AUTOSAR XML (schema 4-1-3)
standard types defined: boolean, sint8, uint16, uint32, uint8, boolean_CompuMethod, boolean_DataConstr, sint8_DataConstr, uint16_DataConstr, uint32_DataConstr, uint8_DataConstr, sint16
package /MICROSAR/Dem_swc/DataTypes
  5 x impl type:
    Dem_DebounceResetStatusType: compu {0=DEM_DEBOUNCE_STATUS_FREEZE, 1=DEM_DEBOUNCE_STATUS_RESET}, range raw 0..255, implementation-data-type=ImplementationDataTypes/uint8
    Dem_DTCFormatType: compu {0=DEM_DTC_FORMAT_OBD, 1=DEM_DTC_FORMAT_UDS, 2=DEM_DTC_FORMAT_J1939}, range raw 0..2, implementation-data-type=ImplementationDataTypes/uint8
    Dem_EventStatusType:
      compu {0=DEM_EVENT_STATUS_PASSED, 1=DEM_EVENT_STATUS_FAILED, 2=DEM_EVENT_STATUS_PREPASSED, 3=DEM_EVENT_STATUS_PREFAILED, 4=DEM_EVENT_STATUS_FDC_THRESHOLD_REACHED, 5=DEM_EVENT_STATUS_PASSED_CONDITIONS_NOT_FULFILLED, 6=DEM_EVENT_STATUS_FAILED_CONDITIONS_NOT_FULFILLED, 7=DEM_EVENT_STATUS_PREPASSED_CONDITIONS_NOT_FULFILLED, 8=DEM_EVENT_STATUS_PREFAILED_CONDITIONS_NOT_FULFILLED}
      range raw 0..255
      implementation-data-type=ImplementationDataTypes/uint8
    Dem_MaxDataValueType: category=ARRAY, sw-calibration-access=READ-ONLY
      element Dem_MaxDataValueTypeElement: array-size=40, array-size-semantics=FIXED-SIZE, implementation-data-type=ImplementationDataTypes/uint8
    Dem_UdsStatusByteType:
      compu {mask 1: 1=DEM_UDS_STATUS_TF (bit 0: TestFailed), mask 2: 2=DEM_UDS_STATUS_TFTOC (bit 1: TestFailedThisOperationCycle), mask 4: 4=DEM_UDS_STATUS_PDTC (bit 2: PendingDTC), mask 8: 8=DEM_UDS_STATUS_CDTC (bit 3: ConfirmedDTC), mask 16: 16=DEM_UDS_STATUS_TNCSLC (bit 4: TestNotCompletedSinceLastClear), mask 32: 32=DEM_UDS_STATUS_TFSLC (bit 5: TestFailedSinceLastClear), mask 64: 64=DEM_UDS_STATUS_TNCTOC (bit 6: TestNotCompletedThisOperationCycle), mask 128: 128=DEM_UDS_STATUS_WIR (bit 7: WarningIndicatorRequested)}
      range raw 0..255
      implementation-data-type=ImplementationDataTypes/uint8
package /MICROSAR/Dem_swc/Interfaces
  client server interface DiagnosticMonitor: is-service=true, service-kind=DIAGNOSTIC-EVENT-MANAGER
    11 x operation:
      GetDTCOfEvent: possible-error=[DEM_E_NO_DTC_AVAILABLE, DiagnosticMonitor/E_NOT_OK]
        arg DTCFormat: type=Dem_DTCFormatType, direction=IN, server-argument-impl-policy=USE-ARGUMENT-TYPE
        arg DTCOfEvent: type=uint32, direction=OUT, server-argument-impl-policy=USE-ARGUMENT-TYPE
      GetEventExtendedDataRecordEx: possible-error=[DEM_BUFFER_TOO_SMALL, DEM_NO_SUCH_ELEMENT, DiagnosticMonitor/E_NOT_OK]
        arg RecordNumber: type=ImplementationDataTypes/uint8, direction=IN, server-argument-impl-policy=USE-ARGUMENT-TYPE
        arg DestBuffer: type=Dem_MaxDataValueType, direction=OUT, server-argument-impl-policy=USE-ARGUMENT-TYPE
        arg BufSize: type=ImplementationDataTypes/uint16, direction=INOUT, server-argument-impl-policy=USE-ARGUMENT-TYPE
      GetEventFailed: possible-error=DiagnosticMonitor/E_NOT_OK
        arg EventFailed: type=ImplementationDataTypes/boolean, direction=OUT, server-argument-impl-policy=USE-ARGUMENT-TYPE
      GetEventFreezeFrameDataEx: possible-error=[DEM_BUFFER_TOO_SMALL, DEM_NO_SUCH_ELEMENT, DiagnosticMonitor/E_NOT_OK]
        4 x arg, all with server-argument-impl-policy=USE-ARGUMENT-TYPE:
          RecordNumber: type=ImplementationDataTypes/uint8, direction=IN
          DataId: type=ImplementationDataTypes/uint16, direction=IN
          DestBuffer: type=Dem_MaxDataValueType, direction=OUT
          BufSize: type=ImplementationDataTypes/uint16, direction=INOUT
      GetEventStatus: possible-error=DiagnosticMonitor/E_NOT_OK
        arg UDSStatusByte: type=Dem_UdsStatusByteType, direction=OUT, server-argument-impl-policy=USE-ARGUMENT-TYPE
      GetEventTested: possible-error=DiagnosticMonitor/E_NOT_OK
        arg EventTested: type=ImplementationDataTypes/boolean, direction=OUT, server-argument-impl-policy=USE-ARGUMENT-TYPE
      GetEventUdsStatus: possible-error=DiagnosticMonitor/E_NOT_OK
        arg UDSStatusByte: type=Dem_UdsStatusByteType, direction=OUT, server-argument-impl-policy=USE-ARGUMENT-TYPE
      GetFaultDetectionCounter: possible-error=[DEM_E_NO_FDC_AVAILABLE, DiagnosticMonitor/E_NOT_OK]
        arg FaultDetectionCounter: type=sint8, direction=OUT, server-argument-impl-policy=USE-ARGUMENT-TYPE
      ResetEventDebounceStatus: possible-error=DiagnosticMonitor/E_NOT_OK
        arg DebounceResetStatus: type=Dem_DebounceResetStatusType, direction=IN, server-argument-impl-policy=USE-ARGUMENT-TYPE
      ResetEventStatus: possible-error=DiagnosticMonitor/E_NOT_OK
      SetEventStatus: possible-error=DiagnosticMonitor/E_NOT_OK
        arg EventStatus: type=Dem_EventStatusType, direction=IN, server-argument-impl-policy=USE-ARGUMENT-TYPE
    5 x error:
      DEM_BUFFER_TOO_SMALL: error-code=21
      DEM_E_NO_DTC_AVAILABLE: error-code=10
      DEM_E_NO_FDC_AVAILABLE: error-code=14
      DEM_NO_SUCH_ELEMENT: error-code=48
      E_NOT_OK: error-code=1
package /UAES/ASW/ApplicationDataTypes
  app type Appl_AcChrgrIntkT2_tTrfSnsr_CUR: category=CURVE, sw-calibration-access=READ-WRITE, sw-calprm-axis-set={sw-axis-index=1, category=COM_AXIS, sw-axis-individual={compu {phys=raw for raw -INF..INF; unit mV}, sw-max-axis-points=30, sw-min-axis-points=30, range raw 0..65535}}, compu {phys=raw*0.1-273.14 for raw -INF..INF; unit DegC}, range raw -32768..32767
  app type T_q0p1_o273p14_DegC_s16: category=VALUE, sw-calibration-access=READ-WRITE, compu {phys=raw*0.1-273.14 for raw -INF..INF; unit DegC}, range raw -32768..32767
  app type U_q1_mV_u16: category=VALUE, sw-calibration-access=READ-WRITE, compu {phys=raw for raw -INF..INF; unit mV}, range raw 0..65535
package /UAES/ASW/CompuMethods
  compu method CM_boolean: 0=FALSE, 1=TRUE
package /UAES/ASW/DataConstrs
  range DC_boolean: raw 0..1
  range DC_sint16: raw -32768..32767
  range DC_uint16: phys 0..6553.5, raw 0..65535
  range DC_uint8: raw 0..255
package /UAES/ASW/DataTypeMappingSets
  data type mapping set DTMS_AcChrgrIntkT2_DD
    data-type-maps:
      application-data-type=Appl_AcChrgrIntkT2_tTrfSnsr_CUR, implementation-data-type=AcChrgrIntkT2_tTrfSnsr_CUR_Type
      application-data-type=T_q0p1_o273p14_DegC_s16, implementation-data-type=sint16
      application-data-type=U_q1_mV_u16, implementation-data-type=ImplementationDataTypes/uint16
package /UAES/ASW/ImplementationDataTypes
  5 x impl type:
    AcChrgrIntkT2_tTrfSnsr_CUR_Type: category=STRUCTURE
      element N1: implementation-data-type=ImplementationDataTypes/uint16
      element BP1: implementation-data-type=rt_Array_U_q1_mV_u16_30
      element Table: implementation-data-type=rt_Array_T_q0p1_o273p14_DegC_s16_30
    rt_Array_T_q0p1_o273p14_DegC_s16_30: category=ARRAY
      element rt_Array_T_q0p1_o273p14_DegC_s16_30: array-size=30, array-size-semantics=FIXED-SIZE, implementation-data-type=T_q0p1_o273p14_DegC_s16
    rt_Array_U_q1_mV_u16_30: category=ARRAY
      element rt_Array_U_q1_mV_u16_30: array-size=30, array-size-semantics=FIXED-SIZE, implementation-data-type=U_q1_mV_u16
    T_q0p1_o273p14_DegC_s16: category=VALUE, base-type=sint16, range raw -32768..32767
    U_q1_mV_u16: category=VALUE, base-type=BaseTypes/uint16, range raw 0..65535
package /UAES/ASW/ImplementationDataTypes/Ground
  4 x constant specification:
    AcChrgrIntkT2_numRawVoltFildPoint_C: value-spec=AcChrgrIntkT2_numRawVoltFildPoint_C:10
    AcChrgrIntkT2_tTrfSnsr_CUR: value-spec=fields=[N:30, X:[10, 13, 16, 20, 25, 33, 42, 55, 73, 99, 136, 170, 213, 272, 345, 438, 560, 715, 911, 1160, 1469, 1840, 2269, 2739, 3221, 3676, 4069, 4380, 4611, 4769], Y:[5731, 5581, 5431, 5281, 5131, 4981, 4831, 4681, 4531, 4381, 4231, 4131, 4031, 3931, 3831, 3731, 3631, 3531, 3431, 3331, 3231, 3131, 3031, 2931, 2831, 2731, 2631, 2531, 2431, 2331]]
    AcChrgrIntkT2_uRawMaxSRC_C: value-spec=4800 mV
    AcChrgrIntkT2_uRawMinSRC_C: value-spec=200 mV
package /UAES/ASW/PortInterfaces
  client server interface IoHwAb_IoSigAdc
    operation Adc_Get: possible-error=IoHwAb_IoSigAdc/E_NOT_OK
      arg id_u16: type=ImplementationDataTypes/uint16, direction=IN, server-argument-impl-policy=USE-ARGUMENT-TYPE
      arg val_s16: type=sint16, direction=OUT, server-argument-impl-policy=USE-ARGUMENT-TYPE
    operation AdcFac_Get: possible-error=IoHwAb_IoSigAdc/E_NOT_OK
      arg id_u16: type=ImplementationDataTypes/uint16, direction=IN, server-argument-impl-policy=USE-ARGUMENT-TYPE
      arg val_s16: type=sint16, direction=OUT, server-argument-impl-policy=USE-ARGUMENT-TYPE
    operation AdcVRMBatt_Get: possible-error=IoHwAb_IoSigAdc/E_NOT_OK
      arg id_u16: type=ImplementationDataTypes/uint16, direction=IN, server-argument-impl-policy=USE-ARGUMENT-TYPE
      arg val_u8: type=ImplementationDataTypes/uint8, direction=OUT, server-argument-impl-policy=USE-ARGUMENT-TYPE
    error E_NOT_OK: error-code=1
  6 x sender receiver interface:
    AcChrgrIntkT2_flgSRCMaxErr: invalidation-policy{data-element=AcChrgrIntkT2_flgSRCMaxErr/Val, handle-invalid=DONT-INVALIDATE}
      data Val: sw-calibration-access=READ-ONLY, type=ImplementationDataTypes/boolean
    AcChrgrIntkT2_flgSRCMinErr: invalidation-policy{data-element=AcChrgrIntkT2_flgSRCMinErr/Val, handle-invalid=DONT-INVALIDATE}
      data Val: sw-calibration-access=READ-ONLY, type=ImplementationDataTypes/boolean
    AcChrgrIntkT2_t: invalidation-policy{data-element=AcChrgrIntkT2_t/Val, handle-invalid=DONT-INVALIDATE}
      data Val: sw-calibration-access=READ-ONLY, type=T_q0p1_o273p14_DegC_s16
    AcChrgrIntkT2_uRaw: invalidation-policy{data-element=AcChrgrIntkT2_uRaw/Val, handle-invalid=DONT-INVALIDATE}
      data Val: sw-calibration-access=READ-ONLY, type=U_q1_mV_u16
    BattU_bVoltEnbPinDiag: invalidation-policy{data-element=BattU_bVoltEnbPinDiag/Val, handle-invalid=DONT-INVALIDATE}
      data Val: sw-calibration-access=READ-ONLY, type=ImplementationDataTypes/boolean
    VehCoorn_stPwrMod: invalidation-policy{data-element=VehCoorn_stPwrMod/Val, handle-invalid=DONT-INVALIDATE}
      data Val: sw-calibration-access=READ-ONLY, type=ImplementationDataTypes/uint8
package /UAES/ASW/SwAddrMethods
  sw addr method CALDATA
package /UAES/ASW/SwComponentTypes
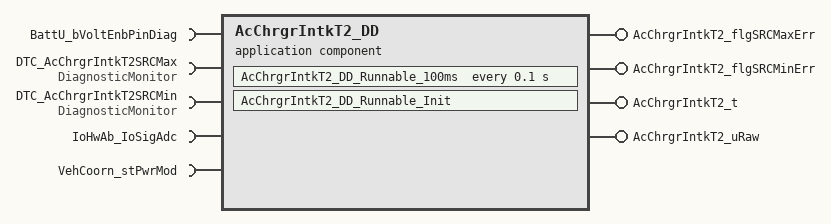
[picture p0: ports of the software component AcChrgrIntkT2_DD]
  application sw component type AcChrgrIntkT2_DD
    4 x provide port:
      AcChrgrIntkT2_flgSRCMaxErr: nonqueued-sender-com-spec{data-element=AcChrgrIntkT2_flgSRCMaxErr/Val, init-value=0}, provided-interface=AcChrgrIntkT2_flgSRCMaxErr
      AcChrgrIntkT2_flgSRCMinErr: nonqueued-sender-com-spec{data-element=AcChrgrIntkT2_flgSRCMinErr/Val, init-value=0}, provided-interface=AcChrgrIntkT2_flgSRCMinErr
      AcChrgrIntkT2_t: nonqueued-sender-com-spec{data-element=AcChrgrIntkT2_t/Val, init-value=0 DegC}, provided-interface=AcChrgrIntkT2_t
      AcChrgrIntkT2_uRaw: nonqueued-sender-com-spec{data-element=AcChrgrIntkT2_uRaw/Val, init-value=0 mV}, provided-interface=AcChrgrIntkT2_uRaw
    5 x require port:
      BattU_bVoltEnbPinDiag: nonqueued-receiver-com-spec{data-element=BattU_bVoltEnbPinDiag/Val, filter=data-filter-type=ALWAYS, init-value=0}, required-interface=BattU_bVoltEnbPinDiag
      DTC_AcChrgrIntkT2SRCMax: required-interface=DiagnosticMonitor
        required-com-specs:
          GetDTCOfEvent
          GetEventExtendedDataRecordEx
          GetEventFailed
          GetEventFreezeFrameDataEx
          GetEventStatus
          GetEventTested
          GetEventUdsStatus
          GetFaultDetectionCounter
          ResetEventDebounceStatus
          ResetEventStatus
          SetEventStatus
      DTC_AcChrgrIntkT2SRCMin: required-interface=DiagnosticMonitor
        required-com-specs:
          GetDTCOfEvent
          GetEventExtendedDataRecordEx
          GetEventFailed
          GetEventFreezeFrameDataEx
          GetEventStatus
          GetEventTested
          GetEventUdsStatus
          GetFaultDetectionCounter
          ResetEventDebounceStatus
          ResetEventStatus
          SetEventStatus
      IoHwAb_IoSigAdc: required-com-specs=[Adc_Get, AdcFac_Get, AdcVRMBatt_Get], required-interface=IoHwAb_IoSigAdc
      VehCoorn_stPwrMod: nonqueued-receiver-com-spec{data-element=VehCoorn_stPwrMod/Val, filter=data-filter-type=ALWAYS, init-value=0}, required-interface=VehCoorn_stPwrMod
    behavior AcChrgrIntkT2_DD_InternalBehavior: data-type-mapping=DTMS_AcChrgrIntkT2_DD
      timing event TMT_AcChrgrIntkT2_DD_Runnable_100ms: start-on-event=AcChrgrIntkT2_DD_Runnable_100ms, period=0.1
      init event AcChrgrIntkT2_DD_InitEvent: start-on-event=AcChrgrIntkT2_DD_Runnable_Init
      runnable AcChrgrIntkT2_DD_Runnable_100ms
        data-read-access:
          access READ_BattU_bVoltEnbPinDiag_Val: accessed-variable=BattU_bVoltEnbPinDiag.Val
          access READ_VehCoorn_stPwrMod_Val: accessed-variable=VehCoorn_stPwrMod.Val
        data-write-access:
          4 x access:
            OUT_AcChrgrIntkT2_flgSRCMaxErr_Val: accessed-variable=AcChrgrIntkT2_flgSRCMaxErr.Val
            OUT_AcChrgrIntkT2_flgSRCMinErr_Val: accessed-variable=AcChrgrIntkT2_flgSRCMinErr.Val
            OUT_AcChrgrIntkT2_t_Val: accessed-variable=AcChrgrIntkT2_t.Val
            OUT_AcChrgrIntkT2_uRaw_Val: accessed-variable=AcChrgrIntkT2_uRaw.Val
        4 x parameter access:
          PA_AcChrgrIntkT2_numRawVoltFildPoint_C: accessed-parameter=AcChrgrIntkT2_numRawVoltFildPoint_C
          PA_AcChrgrIntkT2_tTrfSnsr_CUR: accessed-parameter=AcChrgrIntkT2_tTrfSnsr_CUR
          PA_AcChrgrIntkT2_uRawMaxSRC_C: accessed-parameter=AcChrgrIntkT2_uRawMaxSRC_C
          PA_AcChrgrIntkT2_uRawMinSRC_C: accessed-parameter=AcChrgrIntkT2_uRawMinSRC_C
        9 x sync call:
          SC_DTC_AcChrgrIntkT2SRCMax_GetEventFailed: operation=DTC_AcChrgrIntkT2SRCMax.GetEventFailed, timeout=1E-06
          SC_DTC_AcChrgrIntkT2SRCMax_GetEventTested: operation=DTC_AcChrgrIntkT2SRCMax.GetEventTested, timeout=1E-06
          SC_DTC_AcChrgrIntkT2SRCMax_ResetEventDebounceStatus: operation=DTC_AcChrgrIntkT2SRCMax.ResetEventDebounceStatus, timeout=1E-06
          SC_DTC_AcChrgrIntkT2SRCMax_SetEventStatus: operation=DTC_AcChrgrIntkT2SRCMax.SetEventStatus, timeout=1E-06
          SC_DTC_AcChrgrIntkT2SRCMin_GetEventFailed: operation=DTC_AcChrgrIntkT2SRCMin.GetEventFailed, timeout=1E-06
          SC_DTC_AcChrgrIntkT2SRCMin_GetEventTested: operation=DTC_AcChrgrIntkT2SRCMin.GetEventTested, timeout=1E-06
          SC_DTC_AcChrgrIntkT2SRCMin_ResetEventDebounceStatus: operation=DTC_AcChrgrIntkT2SRCMin.ResetEventDebounceStatus, timeout=1E-06
          SC_DTC_AcChrgrIntkT2SRCMin_SetEventStatus: operation=DTC_AcChrgrIntkT2SRCMin.SetEventStatus, timeout=1E-06
          SC_IoHwAb_IoSigAdc_AdcFac_Get: operation=IoHwAb_IoSigAdc.AdcFac_Get, timeout=0
      runnable AcChrgrIntkT2_DD_Runnable_Init
        data-write-access:
          access OUT_AcChrgrIntkT2_t_Val: accessed-variable=AcChrgrIntkT2_t.Val
          access OUT_AcChrgrIntkT2_uRaw_Val: accessed-variable=AcChrgrIntkT2_uRaw.Val
        4 x parameter access:
          PA_AcChrgrIntkT2_numRawVoltFildPoint_C: accessed-parameter=AcChrgrIntkT2_numRawVoltFildPoint_C
          PA_AcChrgrIntkT2_tTrfSnsr_CUR: accessed-parameter=AcChrgrIntkT2_tTrfSnsr_CUR
          PA_AcChrgrIntkT2_uRawMaxSRC_C: accessed-parameter=AcChrgrIntkT2_uRawMaxSRC_C
          PA_AcChrgrIntkT2_uRawMinSRC_C: accessed-parameter=AcChrgrIntkT2_uRawMinSRC_C
        sync call SC_IoHwAb_IoSigAdc_AdcFac_Get: operation=IoHwAb_IoSigAdc.AdcFac_Get, timeout=0
      shared-parameters:
        4 x parameter data prototype, all with sw-addr-method=CALDATA, sw-calibration-access=READ-WRITE:
          AcChrgrIntkT2_numRawVoltFildPoint_C: type=ImplementationDataTypes/uint8, init-value=constant-reference={short-label=AcChrgrIntkT2_numRawVoltFildPoint_C, constant=AcChrgrIntkT2_numRawVoltFildPoint_C}
          AcChrgrIntkT2_tTrfSnsr_CUR: type=Appl_AcChrgrIntkT2_tTrfSnsr_CUR, init-value=constant-reference={short-label=AcChrgrIntkT2_tTrfSnsr_CUR, constant=AcChrgrIntkT2_tTrfSnsr_CUR}
          AcChrgrIntkT2_uRawMaxSRC_C: type=U_q1_mV_u16, init-value=constant-reference={short-label=AcChrgrIntkT2_uRawMaxSRC_C, constant=AcChrgrIntkT2_uRawMaxSRC_C}
          AcChrgrIntkT2_uRawMinSRC_C: type=U_q1_mV_u16, init-value=constant-reference={short-label=AcChrgrIntkT2_uRawMinSRC_C, constant=AcChrgrIntkT2_uRawMinSRC_C}
  swc implementation AcChrgrIntkT2_DD_imp: behavior=AcChrgrIntkT2_DD_InternalBehavior
    code-descriptors:
      code Default: artifact-descriptors=autosar-engineering-object={short-label=Default, category=SWSRC}
package /UAES/ASW/Units
  unit DegC: display-name=DegC, factor-si-to-unit=1, offset-si-to-unit=0
  unit mV: display-name=mV, factor-si-to-unit=1, offset-si-to-unit=0
  unit NoUnit: factor-si-to-unit=1, offset-si-to-unit=0
